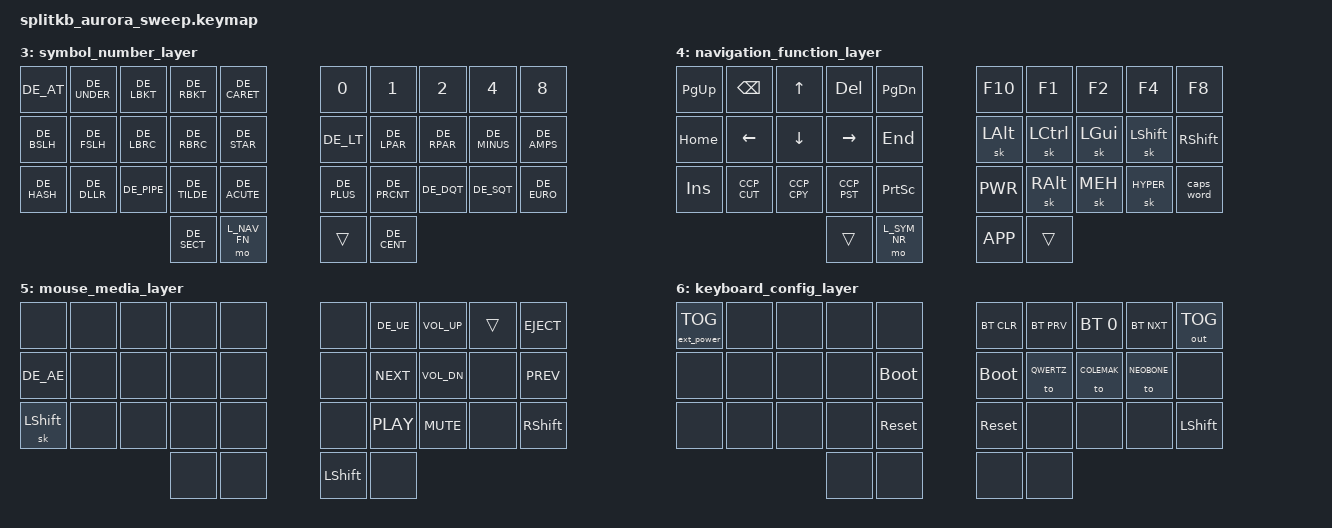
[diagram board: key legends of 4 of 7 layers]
/*
 * Copyright (c) 2022 The ZMK Contributors
 *
 * SPDX-License-Identifier: MIT
 */

#include <behaviors.dtsi>
#include <dt-bindings/zmk/keys.h>
#include <dt-bindings/zmk/bt.h>
#include <dt-bindings/zmk/outputs.h>
/* #include <dt-bindings/zmk/rgb.h> */
#include <dt-bindings/zmk/ext_power.h>
#include "keys_de.h"
#include "custom_keys.h"
#include "custom_combos.h"

&mt {
  flavor = "tap-preferred";
};
&caps_word {
  continue-list = <DE_UNDER DE_MINUS BACKSPACE DELETE>;
};

// pin 1 is blocked by rgb, so use pin 16 as I have no encoders installed
nice_view_spi: &spi0 {
                 compatible = "nordic,nrf-spim";
                 pinctrl-0 = <&spi0_default>;
                 pinctrl-1 = <&spi0_sleep>;
                 pinctrl-names = "default", "sleep";
                 cs-gpios = <&pro_micro 16 GPIO_ACTIVE_HIGH>;  // default is D1 in the pinout
               };

/ {
  conditional_layers {
    compatible = "zmk,conditional-layers";
    tri_layer {
      if-layers = <L_SYM_NR L_NAV_FN>;
      then-layer = <L_ADJUST>;
    };
  };

  keymap {
    compatible = "zmk,keymap";

    // 0. QWERTZ
    qwertz_layer {
      bindings = <
        // ┌─────┬─────┬─────┬─────┬─────┐     ┌─────┬─────┬─────┬─────┬─────┐
        // │  q  │  w  │  e  │  r  │  t  │     │  z  │  u  │  i  │ 3/o │  p  │
        // ├─────┼─────┼─────┼─────┼─────┤     ├─────┼─────┼─────┼─────┼─────┤
        // │  a  │  s  │  d  │  f  │  g  │     │  h  │  j  │  k  │  l  │  ö  │
        // ├─────┼─────┼─────┼─────┼─────┤     ├─────┼─────┼─────┼─────┼─────┤
        // │  y  │  x  │  c  │  v  │  b  │     │  n  │  m  │  ,  │  .  │  ß  │
        // └─────┴─────┴─────┼─────┼─────┤     ├─────┼─────┼─────┴─────┴─────┘
        //                   │2/Esc│1/Ret│     │1/Spc│2/Tab│
        //                   └─────┴─────┘     └─────┴─────┘
        &kp DE_Q      &kp DE_W      &kp DE_E      &kp DE_R      &kp DE_T          &kp DE_Z       &kp DE_U      &kp DE_I        MSMD(DE_O)    &kp DE_P
        &kp DE_A      &kp DE_S     HRML(DE_D,         DE_F,         DE_G)         HRMR(DE_H,         DE_J,         DE_K)       &kp DE_L      &kp DE_OE
        HRMS(DE_Y)    &kp DE_X      &kp DE_C      &kp DE_V      &kp DE_B          &kp DE_N       &kp DE_M      &kp DE_COMMA    &kp DE_DOT    HRMS(DE_SZ)
        /**/                                      NAVFN_ESC     SYMNR_RET         SYMNR_SPC      NAVFN_TAB
        >;
    };

    // 1. COLEMAK
    colemak_layer {
      bindings = <
        // ┌─────┬─────┬─────┬─────┬─────┐     ┌─────┬─────┬─────┬─────┬─────┐
        // │  q  │  w  │  f  │  p  │  b  │     │  j  │  l  │  u  │ 3/z │  ö  │
        // ├─────┼─────┼─────┼─────┼─────┤     ├─────┼─────┼─────┼─────┼─────┤
        // │  a  │  r  │  s  │  t  │  g  │     │  m  │  n  │  e  │  i  │  o  │
        // ├─────┼─────┼─────┼─────┼─────┤     ├─────┼─────┼─────┼─────┼─────┤
        // │  y  │  x  │  c  │  v  │  b  │     │  n  │  m  │  ,  │  .  │  ß  │
        // └─────┴─────┴─────┼─────┼─────┤     ├─────┼─────┼─────┴─────┴─────┘
        //                   │2/Esc│1/Ret│     │1/Spc│2/Tab│
        //                   └─────┴─────┘     └─────┴─────┘
        &kp DE_Q      &kp DE_W      &kp DE_F      &kp DE_P      &kp DE_B          &kp DE_J       &kp DE_L      &kp DE_U        MSMD(DE_Z)    &kp DE_OE
        &kp DE_A      &kp DE_R     HRML(DE_S,         DE_T,         DE_G)         HRMR(DE_M,         DE_N,         DE_E)       &kp DE_I      &kp DE_O
        HRMS(DE_Y)    &kp DE_X      &kp DE_C      &kp DE_D      &kp DE_V          &kp DE_K       &kp DE_H      &kp DE_COMMA    &kp DE_DOT    HRMS(DE_SZ)
        /**/                                      NAVFN_ESC     SYMNR_RET         SYMNR_SPC      NAVFN_TAB
        >;
    };

    // 2. NEO BONE
    default_layer {
      bindings = <
        // ┌─────┬─────┬─────┬─────┬─────┐     ┌─────┬─────┬─────┬─────┬─────┐
        // │  j  │  d  │  u  │  a  │  x  │     │  p  │  h  │  l  │ 3/m │  w  │
        // ├─────┼─────┼─────┼─────┼─────┤     ├─────┼─────┼─────┼─────┼─────┤
        // │  c  │  t  │  i  │  e  │  o  │     │  b  │  n  │  r  │  s  │  g  │
        // ├─────┼─────┼─────┼─────┼─────┤     ├─────┼─────┼─────┼─────┼─────┤
        // │  f  │  v  │  ß  │  q  │  ö  │     │  y  │  z  │  ,  │  .  │  k  │
        // └─────┴─────┴─────┼─────┼─────┤     ├─────┼─────┼─────┴─────┴─────┘
        //                   │2/Esc│1/Ret│     │1/Spc│2/Tab│
        //                   └─────┴─────┘     └─────┴─────┘
        &kp DE_J      &kp DE_D      &kp DE_U      &kp DE_A      &kp DE_X          &kp DE_P       &kp DE_H      &kp DE_L        MSMD(DE_M)    &kp DE_W
        &kp DE_C      &kp DE_T     HRML(DE_I,         DE_E,         DE_O)         HRMR(DE_B,         DE_N,         DE_R)       &kp DE_S      &kp DE_G
        HRMS(DE_F)    &kp DE_V      &kp DE_SZ     &kp DE_Q      &kp DE_OE         &kp DE_Y       &kp DE_Z      &kp DE_COMMA    &kp DE_DOT    HRMS(DE_K)
        /**/                                      NAVFN_ESC     SYMNR_RET         SYMNR_SPC      NAVFN_TAB
        >;
    };

    // 3. L_SYM_NR
    symbol_number_layer {
      bindings = <
        // ┌─────┬─────┬─────┬─────┬─────┐     ┌─────┬─────┬─────┬─────┬─────┐
        // │  @  │  _  │  [  │  ]  │ ^ ° │     │ 0 = │ 1 ! │ 2 " │ 4 $ │ 8 ( │
        // ├─────┼─────┼─────┼─────┼─────┤     ├─────┼─────┼─────┼─────┼─────┤
        // │  \  │  /  │  {  │  }  │  *  │     │ < > │  (  │  )  │ - _ │  &  │
        // ├─────┼─────┼─────┼─────┼─────┤     ├─────┼─────┼─────┼─────┼─────┤
        // │ # ' │  $  │  |  │  ~  │  ´  │     │ + * │  %  │  "  │  '  │  €  │
        // └─────┴─────┴─────┼─────┼─────┤     ├─────┼─────┼─────┴─────┴─────┘
        //                   │ (§) │ ___ │     │ ___ │  ¢  │
        //                   └─────┴─────┘     └─────┴─────┘
        &kp DE_AT     &kp DE_UNDER  &kp DE_LBKT   &kp DE_RBKT   &kp DE_CARET      &kp N0        &kp N1        &kp N2        &kp N4        &kp N8
        &kp DE_BSLH   &kp DE_FSLH   &kp DE_LBRC   &kp DE_RBRC   &kp DE_STAR       &kp DE_LT     &kp DE_LPAR   &kp DE_RPAR   &kp DE_MINUS  &kp DE_AMPS
        &kp DE_HASH   &kp DE_DLLR   &kp DE_PIPE   &kp DE_TILDE  &kp DE_ACUTE      &kp DE_PLUS   &kp DE_PRCNT  &kp DE_DQT    &kp DE_SQT    &kp DE_EURO
        /**/                                      &kp DE_SECT   &mo L_NAV_FN      &trans        &kp DE_CENT
        >;
    };

    // 4. L_NAV_FN
    navigation_function_layer {
      bindings = <
        // ┌─────┬─────┬─────┬─────┬─────┐     ┌─────┬─────┬─────┬─────┬─────┐
        // │PgUp │ BSp │  ↑  │ Del │PgDn │     │ F10 │  F1 │  F2 │  F4 │  F8 │
        // ├─────┼─────┼─────┼─────┼─────┤     ├─────┼─────┼─────┼─────┼─────┤
        // │Home │  ←  │  ↓  │  →  │ End │     │OsAlt│OsCtl│OsGui│OsSft│ RSft│
        // ├─────┼─────┼─────┼─────┼─────┤     ├─────┼─────┼─────┼─────┼─────┤
        // │ Ins │ Cut │Copy │Paste│PrScr│     │Power│OsAGr│OsMeh│OsHyp│CapsW│
        // └─────┴─────┴─────┼─────┼─────┤     ├─────┼─────┼─────┴─────┴─────┘
        //                   │     │     │     │ App │     │
        //                   └─────┴─────┘     └─────┴─────┘
        &kp PG_UP     &kp BSPC      &kp UP        &kp DEL       &kp PG_DN         &kp F10       &kp F1        &kp F2        &kp F4        &kp F8
        &kp HOME      &kp LEFT      &kp DOWN      &kp RIGHT     &kp END           &sk LALT      &sk LCTRL     &sk LGUI      &sk LSHFT     &kp RSHFT
        &kp INS       &kp CCP_CUT   &kp CCP_CPY   &kp CCP_PST   &kp PSCRN         &kp C_PWR     &sk RALT      &sk MEH       &sk HYPER     &caps_word
        /**/                                      &trans        &mo L_SYM_NR      &kp K_APP     &trans
        >;
    };

    // 5. L_MS_MED
    mouse_media_layer {
      bindings = <
        // ┌─────┬─────┬─────┬─────┬─────┐     ┌─────┬─────┬─────┬─────┬─────┐
        // │ vvv │ <<< │  ↑  │ >>> │ ^^^ │     │MsSp+│  ü  │ Vol+│ (v) │Eject│
        // ├─────┼─────┼─────┼─────┼─────┤     ├─────┼─────┼─────┼─────┼─────┤
        // │  ä  │  ←  │  ↓  │  →  │Pause│     │MsSpN│ Next│ Vol-│ XXX │ Prev│
        // ├─────┼─────┼Mouse┼─────┼─────┤     ├─────┼─────┼─────┼─────┼─────┤
        // │ XXX │ MB4 │ MB3 │ MB5 │SrlLk│     │MsSp-│ Play│ Mute│ XXX │RShft│
        // └─────┴─────┴─────┼─────┼─────┤     ├─────┼─────┼─────┴─────┴─────┘
        //                   │ MB2 │ MB1 │     │LShft│ MB3 │
        //                   └─────┴─────┘     └─────┴─────┘
        &none         &none         &none         &none         &none             &none         &kp DE_UE     &kp C_VOL_UP  &trans   &kp C_EJECT
        &kp DE_AE     &none         &none         &none         &none             &none         &kp C_NEXT    &kp C_VOL_DN  &none    &kp C_PREV
        &sk LSHIFT    &none         &none         &none         &none             &none         &kp C_PLAY    &kp C_MUTE    &none    &kp RSHFT
        /**/                                      &none         &none             &kp LSHFT     &none
        >;
    };

    // 6. L_ADJUST
    keyboard_config_layer {
      bindings = <
        // ┌─────┬─────┬─────┬─────┬─────┐     ┌─────┬─────┬─────┬─────┬─────┐
        // │ TOGG│(Md-)│(Md+)│ XXX │ XXX │     │ BtC │ Bt← │ Bt0 │ Bt→ │ B/U │
        // ├─────┼─────┼─────┼─────┼─────┤     ├─────┼─────┼─────┼─────┼─────┤
        // │(Sp+)│(Vl+)│(St+)│(Hu+)│BOOTL│     │BOOTL│QWERT│COLMK│ BONE│LYPND│
        // ├─────┼─────┼─────┼─────┼─────┤     ├─────┼─────┼─────┼─────┼─────┤
        // │(Sp-)│(Vl-)│(St-)│(Hu-)│RESET│     │RESET│ ASET│ARTSN│ XXX │ Sft │
        // └─────┴─────┴─────┼─────┼─────┤     ├─────┼─────┼─────┴─────┴─────┘
        //                   │     │     │     │     │     │
        //                   └─────┴─────┘     └─────┴─────┘
        &ext_power EP_TOG  &none    &none         &none         &none                &bt BT_CLR    &bt BT_PRV    &bt BT_SEL 0  &bt BT_NXT    &out OUT_TOG
        &none              &none    &none         &none         &bootloader          &bootloader   &to QWERTZ    &to COLEMAK   &to NEOBONE   &none
        &none              &none    &none         &none         &sys_reset           &sys_reset    &none         &none         &none         &kp LSHFT
        // &rgb_ug RGB_TOG  &none            &none            &sys_reset       &bootloader          &bootloader   &bt BT_SEL 1  &bt BT_SEL 2  &bt BT_SEL 3  &bt BT_SEL 4
        // &rgb_ug RGB_SPI  &rgb_ug RGB_BRI  &rgb_ug RGB_SAI  &rgb_ug RGB_HUI  &rgb_ug RGB_EFF      &bt BT_CLR    &bt BT_PRV    &bt BT_SEL 0  &bt BT_NXT    &out OUT_TOG
        // &rgb_ug RGB_SPD  &rgb_ug RGB_BRD  &rgb_ug RGB_SAD  &rgb_ug RGB_HUD  &rgb_ug RGB_EFR      &sys_reset    &none         &none         &none         &kp LSHFT
        /**/                                      &none         &none             &none         &none
        >;
    };

  };

};
